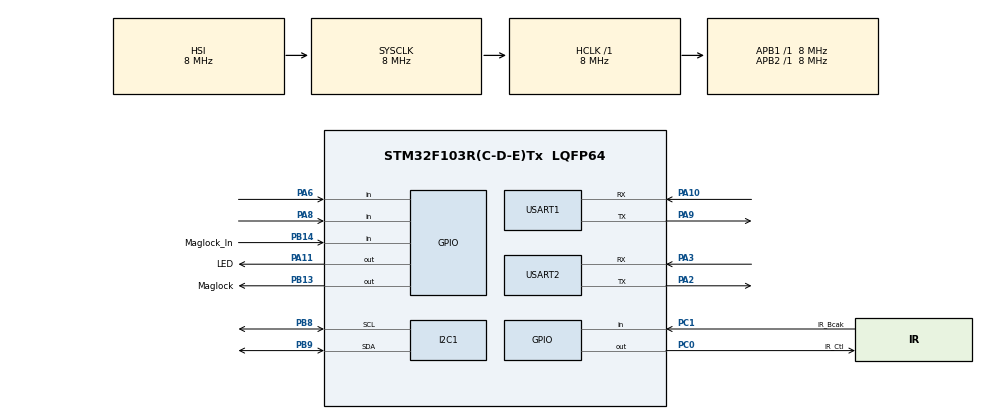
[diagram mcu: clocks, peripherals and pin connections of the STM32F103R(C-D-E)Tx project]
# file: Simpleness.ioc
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Dma.I2C1_TX.0.Direction=DMA_MEMORY_TO_PERIPH
Dma.I2C1_TX.0.Instance=DMA1_Channel6
Dma.I2C1_TX.0.MemDataAlignment=DMA_MDATAALIGN_BYTE
Dma.I2C1_TX.0.MemInc=DMA_MINC_ENABLE
Dma.I2C1_TX.0.Mode=DMA_NORMAL
Dma.I2C1_TX.0.PeriphDataAlignment=DMA_PDATAALIGN_BYTE
Dma.I2C1_TX.0.PeriphInc=DMA_PINC_DISABLE
Dma.I2C1_TX.0.Priority=DMA_PRIORITY_LOW
Dma.Request0=I2C1_TX
I2C1.I2C_Mode=I2C_Fast
Mcu.Family=STM32F1
Mcu.Name=STM32F103R(C-D-E)Tx
Mcu.Package=LQFP64
NVIC.DMA1_Channel6_IRQn=true\:0\:0\:false\:false\:true\:false\:true\:true
NVIC.PriorityGroup=NVIC_PRIORITYGROUP_4
NVIC.TIM6_IRQn=true\:0\:0\:false\:false\:true\:true\:true\:true
NVIC.USART2_IRQn=true\:0\:0\:false\:false\:true\:true\:true\:true
PA10.Mode=Asynchronous
PA10.Signal=USART1_RX
PA11.GPIO_Label=LED
PA11.GPIO_PuPd=GPIO_PULLUP
PA11.PinState=GPIO_PIN_SET
PA11.Signal=GPIO_Output
PA13.Mode=Serial_Wire
PA13.Signal=SYS_JTMS-SWDIO
PA14.Mode=Serial_Wire
PA14.Signal=SYS_JTCK-SWCLK
PA2.Mode=Asynchronous
PA2.Signal=USART2_TX
PA3.Mode=Asynchronous
PA3.Signal=USART2_RX
PA6.Signal=GPIO_Input
PA8.GPIO_PuPd=GPIO_PULLUP
PA8.Signal=GPIO_Input
PA9.Mode=Asynchronous
PA9.Signal=USART1_TX
PB13.GPIO_Label=Maglock
PB13.GPIO_PuPd=GPIO_PULLUP
PB13.PinState=GPIO_PIN_SET
PB13.Signal=GPIO_Output
PB14.GPIO_Label=Maglock_In
PB14.GPIO_PuPd=GPIO_PULLUP
PB14.Signal=GPIO_Input
PB8.Mode=I2C
PB8.Signal=I2C1_SCL
PB9.Mode=I2C
PB9.Signal=I2C1_SDA
PC0.GPIO_Label=IR_Ctl
PC0.GPIO_PuPd=GPIO_PULLUP
PC0.Signal=GPIO_Output
PC1.GPIO_Label=IR_Bcak
PC1.GPIO_PuPd=GPIO_PULLUP
PC1.Signal=GPIO_Input
PD0-OSC_IN.Mode=HSE-External-Oscillator
PD0-OSC_IN.Signal=RCC_OSC_IN
PD1-OSC_OUT.Mode=HSE-External-Oscillator
PD1-OSC_OUT.Signal=RCC_OSC_OUT
ProjectManager.HeapSize=0x200
ProjectManager.StackSize=0x400
ProjectManager.TargetToolchain=MDK-ARM V5.32
RCC.AHBFreq_Value=8000000
RCC.APB1Freq_Value=8000000
RCC.APB1TimFreq_Value=8000000
RCC.APB2Freq_Value=8000000
RCC.APB2TimFreq_Value=8000000
RCC.HCLKFreq_Value=8000000
RCC.PLLMUL=RCC_PLL_MUL9
RCC.PLLSourceVirtual=RCC_PLLSOURCE_HSE
RCC.SYSCLKFreq_VALUE=8000000
RCC.USBFreq_Value=72000000
TIM6.Period=1000-1
TIM6.Prescaler=72-1
USART1.VirtualMode=VM_ASYNC
USART2.VirtualMode=VM_ASYNC
VP_TIM6_VS_ClockSourceINT.Mode=Enable_Timer
board=custom

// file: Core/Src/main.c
/* USER CODE BEGIN Header */
/**
  ******************************************************************************
  * @file           : main.c
  * @brief          : Main program body
  ******************************************************************************
  * @attention
  *
  * Copyright (c) 2024 STMicroelectronics.
  * All rights reserved.
  *
  * This software is licensed under terms that can be found in the LICENSE file
  * in the root directory of this software component.
  * If no LICENSE file comes with this software, it is provided AS-IS.
  *
  ******************************************************************************
  */
/* USER CODE END Header */
#include "main.h"
#include "dma.h"
#include "i2c.h"
#include "tim.h"
#include "usart.h"
#include "gpio.h"

/* USER CODE BEGIN Includes */
#include "Run.h"
#include <stdint.h>  // 新增：用于标准整数类型定义
/* USER CODE END Includes */

/* USER CODE BEGIN PD */
// 新增：SR602人体红外传感器引脚定义（根据实际硬件修改）
//#define SR602_PIN    GPIO_PIN_1
//#define SR602_PORT   GPIOC

// 新增：OLED屏幕控制引脚定义（根据实际硬件修改）
//#define OLED_POWER_PIN    GPIO_PIN_2
//#define OLED_POWER_PORT   GPIOC

// 新增：OLED亮屏超时时间（3分钟，单位：毫秒）
//#define OLED_TIMEOUT_MS   180000
/* USER CODE END PD */

/* USER CODE BEGIN PV */
// 新增：状态变量
//uint8_t oled_on_flag = 0;       // OLED状态：0-关闭，1-开启
//uint32_t oled_on_timestamp = 0; // 记录OLED开启的时间戳
/* USER CODE END PV */

void SystemClock_Config(void);
/* USER CODE BEGIN PFP */
// 新增：函数声明
//void SR602_Init(void);          // 初始化人体传感器
//uint8_t SR602_Detect(void);     // 检测是否有人靠近
//void OLED_SetPower(uint8_t on); // 控制OLED电源
/* USER CODE END PFP */

/* USER CODE BEGIN 0 */
// 新增：初始化SR602传感器（配置为输入模式）
//void SR602_Init(void)
//{
//  GPIO_InitTypeDef GPIO_InitStruct = {0};
//
//  // 使能传感器所在GPIO端口时钟
//  __HAL_RCC_GPIOC_CLK_ENABLE();
//
//  // 配置传感器引脚为输入，启用内部上拉（SR602检测到人体输出高电平）
//  GPIO_InitStruct.Pin = SR602_PIN;
//  GPIO_InitStruct.Mode = GPIO_MODE_INPUT;
//  GPIO_InitStruct.Pull = GPIO_PULLUP;
//  GPIO_InitStruct.Speed = GPIO_SPEED_FREQ_LOW;
//  HAL_GPIO_Init(SR602_PORT, &GPIO_InitStruct);
//}

//// 新增：检测人体靠近状态
//uint8_t SR602_Detect(void)
//{
//  // 返回1表示检测到人体，0表示未检测到（根据传感器实际输出电平调整）
//  return HAL_GPIO_ReadPin(SR602_PORT, SR602_PIN);
//}

// 新增：控制OLED电源（0-关闭，1-开启）
//void OLED_SetPower(uint8_t on)
//{
//  if (on)
//  {
//    // 开启OLED（根据实际电路修改，此处假设高电平开启）
//    HAL_GPIO_WritePin(OLED_POWER_PORT, OLED_POWER_PIN, GPIO_PIN_SET);
//    oled_on_flag = 1;
//    oled_on_timestamp = HAL_GetTick(); // 记录开启时间
//  }
//  else
//  {
//    // 关闭OLED
//    HAL_GPIO_WritePin(OLED_POWER_PORT, OLED_POWER_PIN, GPIO_PIN_RESET);
//    oled_on_flag = 0;
//  }
//}
/* USER CODE END 0 */

int main(void)
{

  /* MCU Configuration--------------------------------------------------------*/

  /* Reset of all peripherals, Initializes the Flash interface and the Systick. */
  HAL_Init();

  /* Configure the system clock */
  SystemClock_Config();

  /* Initialize all configured peripherals */
  MX_GPIO_Init();
  MX_DMA_Init();
  MX_I2C1_Init();
  MX_USART2_UART_Init();
  MX_USART1_UART_Init();
  MX_TIM6_Init();
  /* USER CODE BEGIN 2 */
  Run_Init();
//  SR602_Init();               // 新增：初始化人体传感器
//  OLED_SetPower(0);           // 新增：初始关闭OLED（满足"一开始屏幕暗"）
  uint16_t action;
  /* USER CODE END 2 */

  /* Infinite loop */
  while (1)
  {

    /* USER CODE BEGIN 3 */
    Run();

    // 新增：人体检测逻辑
//    if (SR602_Detect() == 1)  // 检测到有人靠近
//    {
//      if (oled_on_flag == 0)  // 如果当前OLED是关闭的
//      {
//        OLED_SetPower(1);     // 点亮OLED
//      }
//      else                    // 如果已经点亮
//      {
//        oled_on_timestamp = HAL_GetTick(); // 刷新超时计时（重新计算3分钟）
//      }
//    }
//
//    // 新增：超时关闭逻辑（无人靠近时，3分钟后自动关闭）
//    if (oled_on_flag == 1)
//    {
//      if ((HAL_GetTick() - oled_on_timestamp) >= OLED_TIMEOUT_MS)
//      {
//        OLED_SetPower(0);     // 超时关闭
//      }
//    }

//    HAL_Delay(200);  // 新增：降低检测频率，减少CPU占用
  }
  /* USER CODE END 3 */
}

void SystemClock_Config(void)
{
  RCC_OscInitTypeDef RCC_OscInitStruct = {0};
  RCC_ClkInitTypeDef RCC_ClkInitStruct = {0};

  /** Initializes the RCC Oscillators according to the specified parameters
  * in the RCC_OscInitTypeDef structure.
  */
  RCC_OscInitStruct.OscillatorType = RCC_OSCILLATORTYPE_HSI;
  RCC_OscInitStruct.HSIState = RCC_HSI_ON;
  RCC_OscInitStruct.HSICalibrationValue = RCC_HSICALIBRATION_DEFAULT;
  RCC_OscInitStruct.PLL.PLLState = RCC_PLL_NONE;
  if (HAL_RCC_OscConfig(&RCC_OscInitStruct) != HAL_OK)
  {
    Error_Handler();
  }

  /** Initializes the CPU, AHB and APB buses clocks
  */
  RCC_ClkInitStruct.ClockType = RCC_CLOCKTYPE_HCLK|RCC_CLOCKTYPE_SYSCLK
                              |RCC_CLOCKTYPE_PCLK1|RCC_CLOCKTYPE_PCLK2;
  RCC_ClkInitStruct.SYSCLKSource = RCC_SYSCLKSOURCE_HSI;
  RCC_ClkInitStruct.AHBCLKDivider = RCC_SYSCLK_DIV1;
  RCC_ClkInitStruct.APB1CLKDivider = RCC_HCLK_DIV1;
  RCC_ClkInitStruct.APB2CLKDivider = RCC_HCLK_DIV1;

  if (HAL_RCC_ClockConfig(&RCC_ClkInitStruct, FLASH_LATENCY_0) != HAL_OK)
  {
    Error_Handler();
  }
}

void Error_Handler(void)
{
  __disable_irq();
  while (1)
  {
  }
}
